# M3V6 register map
File version: 0.1
TOSHIBA Cortex-M3 MCU
Registers are 32-bit, read-write, reset 0x0 unless marked. A register's access mark holds for its fields unless they carry their own. Offsets are from the block's base; lines under a group give offsets from that group; [hi:lo] are bit positions; {n}, {i} and the like mark numbered series; 'fields as' and 'values as' point back to an identical list; <NAME> marks a mode.

## Memory map
0x40000000 PA blocks up to offset 0x3C — General Purpose Input_Output Port (PA)
0x40000040 PB blocks up to offset 0x3C — General Purpose Input_Output Port (PB)
0x40000080 PC blocks up to offset 0x3C — General Purpose Input_Output Port (PC)
0x400000C0 PD blocks up to offset 0x3C — General Purpose Input_Output Port (PD)
0x40000100 PE blocks up to offset 0x3C — General Purpose Input_Output Port (PE)
0x40000140 PF blocks up to offset 0x3C — General Purpose Input_Output Port (PF)
0x40000180 PG blocks up to offset 0x3C — General Purpose Input_Output Port (PG)
0x400001C0 PH blocks up to offset 0x3C — General Purpose Input_Output Port (PH)
0x40000200 PI blocks up to offset 0x3C — General Purpose Input_Output Port (PI)
0x40000240 PJ blocks up to offset 0x3C — General Purpose Input_Output Port (PJ)
0x400002C0 PL blocks up to offset 0x3C — General Purpose Input_Output Port (PL)
0x40000300 PM blocks up to offset 0x3C — General Purpose Input_Output Port (PM)
0x40000340 PN blocks up to offset 0x3C — General Purpose Input_Output Port (PN)
0x40000380 PP blocks up to offset 0x3C — General Purpose Input_Output Port (PP)
0x40010000 TB0 size 0x30 — 16-bit Timer_Event Counter (TB)
0x40010040 TB1 size 0x30
0x40010080 TB2 size 0x30
0x400100C0 TB3 size 0x30
0x40010100 TB4 size 0x30
0x40010140 TB5 size 0x30
0x40010180 TB6 size 0x30
0x400101C0 TB7 size 0x30
0x40020000 SBI size 0x18 — Serial Bus Interface (SBI)
0x40020080 SC0 size 0x34 — Serial Channel (SC)
0x400200C0 SC1 size 0x34
0x40020100 SC2 size 0x34
0x40030000 AD blocks up to offset 0xD8 — Analog-to-Digital Converter (AD)
0x40040000 WD size 0x8 — Watchdog Timer (WD)
0x40040100 RTC blocks up to offset 0xD — Real Time Clock (RTC)
0x40040200 CG size 0x34 — Clock Generator (CG)
0x40040400 RMC size 0x38 — Remote Control Signal Preprocessor (RMC)
0x40040800 OFD blocks up to offset 0x20 — Oscillation Frequency Detector (OFD)
0x40040900 VD size 0x4 — Voltage Detection Circuit (VD)
0x40060000 NF size 0x8 — DigitalNoizeFilterClockControl
0x400C0000 SSP size 0x24 — Synchronous Serial Port (SSP)
0x400C2000 UART blocks up to offset 0x54
0x41FFF000 FC blocks up to offset 0x3C — Flash Control (FC)

## PA — General Purpose Input_Output Port (PA)
Base 0x40000000
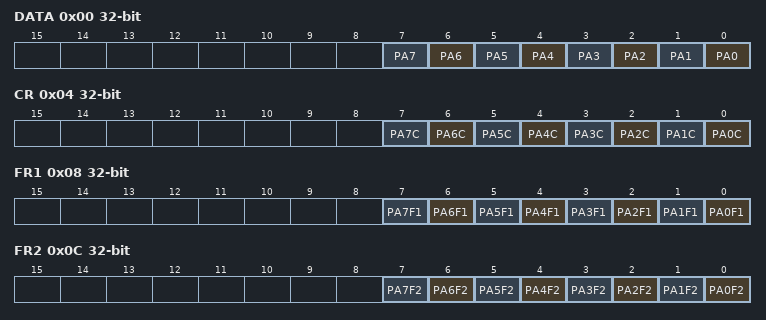
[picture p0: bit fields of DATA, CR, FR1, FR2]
0x00 DATA — PA Data Register
  [n] PA{n} (n=0..7)
0x04 CR — PA Control Register
  [n] PA{n}C (n=0..7)
0x08 FR1 — PA Function Register 1
  [n] PA{n}F1 (n=0..7)
0x0C FR2 — PA Function Register 2
  [n] PA{n}F2 (n=0..7)
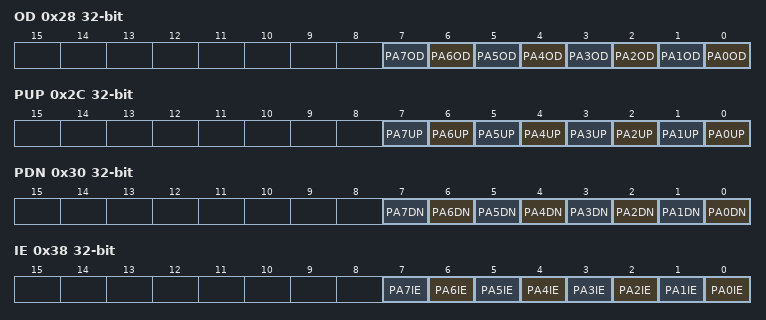
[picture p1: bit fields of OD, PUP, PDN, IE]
0x28 OD — PA Open Drain Control Register
  [n] PA{n}OD (n=0..7)
0x2C PUP — PA Pull-Up Control Register
  [n] PA{n}UP (n=0..7)
0x30 PDN — PA Pull-Down Control Register
  [n] PA{n}DN (n=0..7)
0x38 IE — PA Input Enable Control Register
  [n] PA{n}IE (n=0..7)

## PB — General Purpose Input_Output Port (PB)
Base 0x40000040
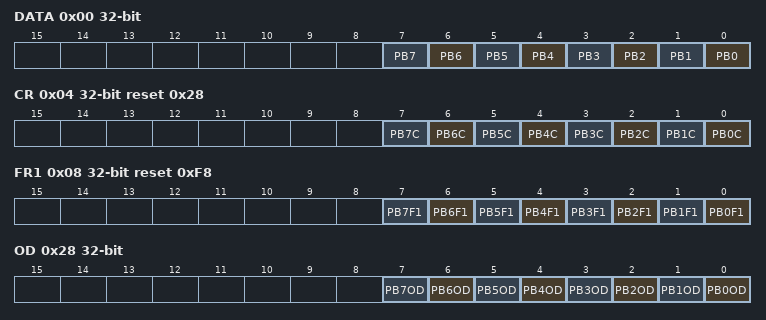
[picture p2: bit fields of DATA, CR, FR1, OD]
0x00 DATA — PB Data Register
  [n] PB{n} (n=0..7)
0x04 CR reset 0x28 — PB Control Register
  [n] PB{n}C (n=0..7)
0x08 FR1 reset 0xF8 — PB Function Register 1
  [n] PB{n}F1 (n=0..7)
0x28 OD — PB Open Drain Control Register
  [n] PB{n}OD (n=0..7)
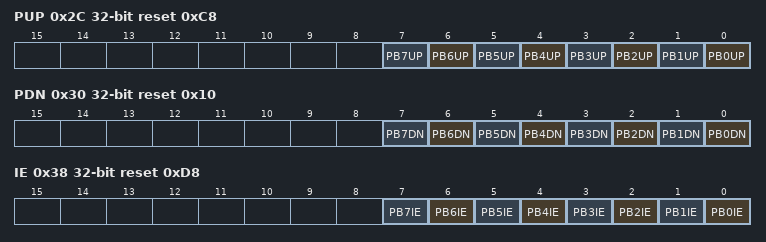
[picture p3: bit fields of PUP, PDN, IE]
0x2C PUP reset 0xC8 — PB Pull-Up Control Register
  [n] PB{n}UP (n=0..7)
0x30 PDN reset 0x10 — PB Pull-Down Control Register
  [n] PB{n}DN (n=0..7)
0x38 IE reset 0xD8 — PB Input Enable Control Register
  [n] PB{n}IE (n=0..7)

## PC — General Purpose Input_Output Port (PC)
Base 0x40000080
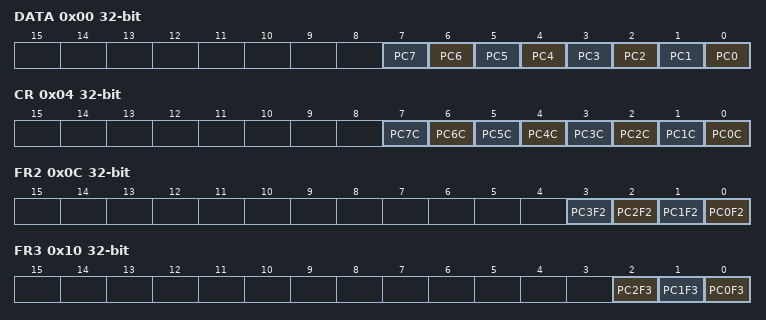
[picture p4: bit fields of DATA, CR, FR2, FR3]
0x00 DATA — PC Data Register
  [n] PC{n} (n=0..7)
0x04 CR — PC Control Register
  [n] PC{n}C (n=0..7)
0x0C FR2 — PC Function Register 2
  [n] PC{n}F2 (n=0..3)
0x10 FR3 — PC Function Register 3
  [2] PC2F3, [1] PC1F3, [0] PC0F3
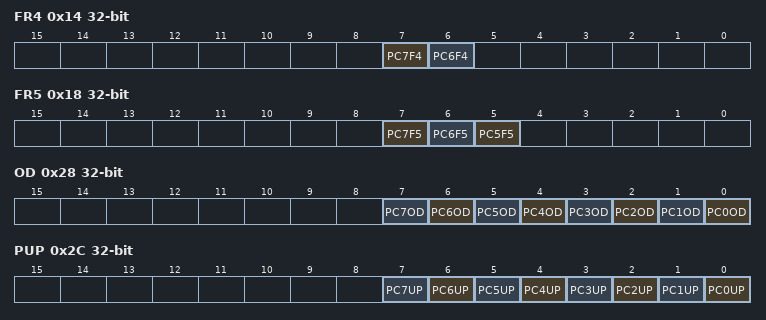
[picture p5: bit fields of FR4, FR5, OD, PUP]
0x14 FR4 — PC Function Register 4
  [7] PC7F4, [6] PC6F4
0x18 FR5 — PC Function Register 5
  [7] PC7F5, [6] PC6F5, [5] PC5F5
0x28 OD — PC Open Drain Control Register
  [n] PC{n}OD (n=0..7)
0x2C PUP — PC Pull-Up Control Register
  [n] PC{n}UP (n=0..7)
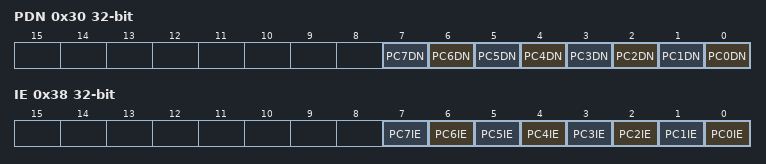
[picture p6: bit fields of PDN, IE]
0x30 PDN — PC Pull-Down Control Register
  [n] PC{n}DN (n=0..7)
0x38 IE — PC Input Enable Control Register
  [n] PC{n}IE (n=0..7)
